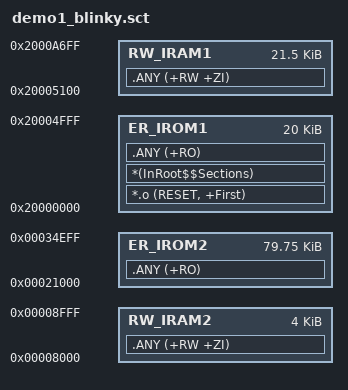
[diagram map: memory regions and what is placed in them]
; *************************************************************
; *** Scatter-Loading Description File generated by uVision ***
; *************************************************************

LR_IROM1 0x20000000 0x00005000  {    ; load region size_region
  ER_IROM1 0x20000000 0x00005000  {  ; load address = execution address
   *.o (RESET, +First)
   *(InRoot$$Sections)
   .ANY (+RO)
  }
  RW_IRAM1 0x20005100 0x00005600  {  ; RW data
   .ANY (+RW +ZI)
  }
  RW_IRAM2 0x00008000 0x00001000  {
   .ANY (+RW +ZI)
  }
}

LR_IROM2 0x00021000 0x00013F00  {
  ER_IROM2 0x00021000 0x00013F00  {  ; load address = execution address
   .ANY (+RO)
  }
}
